# pse84_a0 register map
Vendor: Infineon Technologies; Series: PSE84_A0; File version: 1.0
CPU: CM33 r0p1, little endian, MPU, FPU, VTOR, 3 interrupt priority bits
Registers are 32-bit, read-write, reset 0x0 unless marked. A register's access mark holds for its fields unless they carry their own. Offsets are from the block's base; [hi:lo] are bit positions; lines under a group give offsets from that group; {n}, {i} and the like mark numbered series; 'fields as' and 'values as' point back to an identical list.

## GFXSS (part 2 of 4)
Base 0x44800000
0x1000 GFXSS_DC group — Display Controller.
  0x00 MXDC group — Platform IP standard configuration for DC.
    0x00 CTL — IP control.
      [31] ENABLED — IP enable bit. When disabled (value 0), the functional state of the DCNano core is reset and its clock input gated. Access to MMIO of the core results in an AHB error response. Note, that the effect of this bit is delayed (see STATUS.CORE_RST). The core must be idle (no outstanding or pending AXI transactions) before clearing this bit.
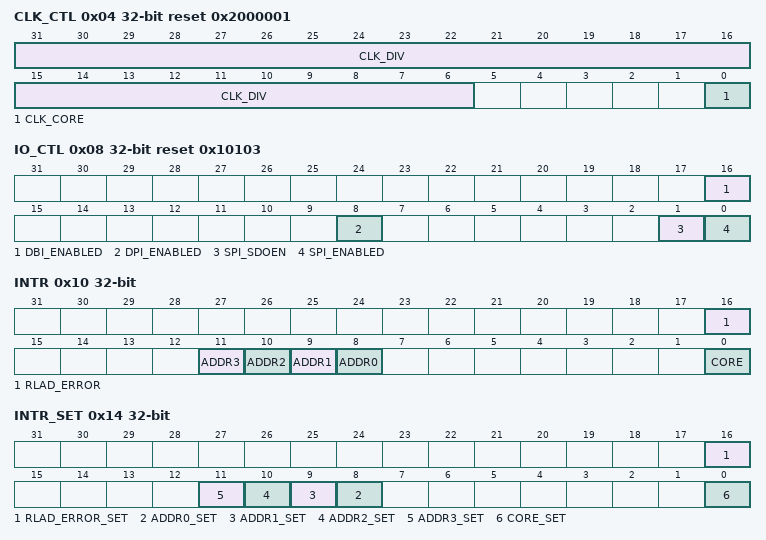
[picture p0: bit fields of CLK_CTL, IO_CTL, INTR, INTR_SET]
    0x04 CLK_CTL reset 0x2000001 — Clock control.
      [31:6] CLK_DIV — Setup of the fractional divider to generate clk_hf_div. In DPI mode the output is the pixel clock. In DBI Type C mode it's two times the serial clock. Format of programmed value is unsigned fix-point 10.16. It must not be set to a value smaller than 2.0 (= 0x020000). It can be set to 0, which results in no clock being generated. Change only while CTL.ENABLED is off.
      [0] CLK_CORE — Setup for DC core and AXI clock. Must only be set to 0 if clk_hf is not faster than 200 MHz. Change only while CTL.ENABLED is off.
        0=HF_DIV1 (Core clock is clk_hf.); 1=HF_DIV2 (Core clock is clk_hf divided by 2.)
    0x08 IO_CTL reset 0x10103 — IO enable control.
      [16] DBI_ENABLED — Enable control for IO cells in DBI Type A/B mode (1 = enabled). CTL.ENABLED must also be 1.
      [8] DPI_ENABLED — Enable control for IO cells in DPI mode (1 = enabled). CTL.ENABLED must also be 1.
      [1] SPI_SDOEN — Controls if the enable for spi_dout is separately controlled by the DCNano core with dbiTypecSdoEn signal (0 = yes, 1 = no). Field has no effect if SPI_ENABLED is 0.
      [0] SPI_ENABLED — Enable control for IO cells in DBI Type C mode (1 = enabled). CTL.ENABLED must also be 1.
    0x0C STATUS ro reset 0x1 — IP status.
      [0] CORE_RST — Reset state of the DCNano core (1 = in reset). This state is delayed to GFXSS_DC reset. After reset de-activation it has to be checked for value 0 before the core can be used. After activation it has to be checked for value 1 before turning off the external clk_hf source.
    0x10 INTR — Interrupt status.
      [16] RLAD_ERROR — The RLAD decoder has entered fail state (see RLAD_STATUS register). Writing a '1' to this field will reset the bit.
      [n+8] ADDR{n} (n=0..3) — Read access to INT_ADDR{n} completed. Writing a '1' to this field will reset the bit.
      [0] CORE — DCNano core has signalled an interrupt. Writing a '1' to this field will reset the bit. Interrupt status inside the core is not affected by this.
    0x14 INTR_SET — Interrupt set bits.
      [16] RLAD_ERROR_SET — Write this field with '1' to set corresponding INTR field (a write of '0' has no effect).
      [n+8] ADDR{n}_SET (n=0..3) — Write this field with '1' to set corresponding INTR field (a write of '0' has no effect).
      [0] CORE_SET — Write this field with '1' to set corresponding INTR field (a write of '0' has no effect).
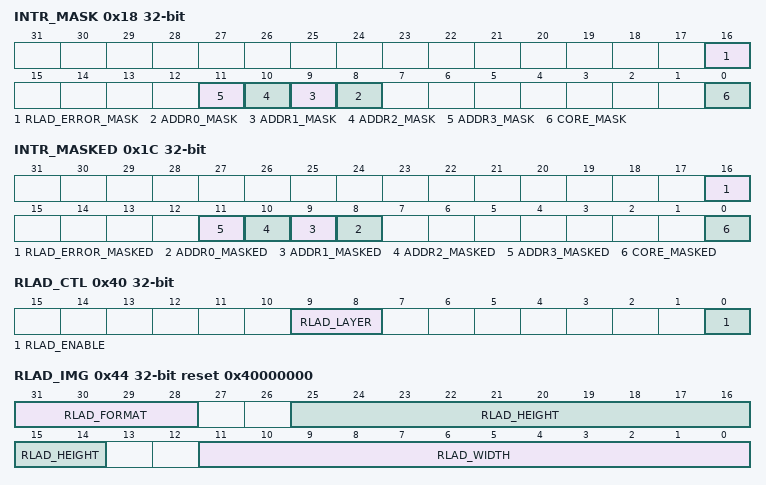
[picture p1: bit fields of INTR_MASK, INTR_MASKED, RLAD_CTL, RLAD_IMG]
    0x18 INTR_MASK — Interrupt mask bits.
      [16] RLAD_ERROR_MASK — Mask for corresponding field in INTR register.
      [n+8] ADDR{n}_MASK (n=0..3) — Mask for corresponding field in INTR register.
      [0] CORE_MASK — Mask for corresponding field in INTR register.
    0x1C INTR_MASKED ro — Interrupt masked bits.
      [16] RLAD_ERROR_MASKED — Logical AND of corresponding INTR and INTR_MASK fields.
      [n+8] ADDR{n}_MASKED (n=0..3) — Logical AND of corresponding INTR and INTR_MASK fields.
      [0] CORE_MASKED — Logical AND of corresponding INTR and INTR_MASK fields.
    0x20 ADDR0_INT — Address 0 for interrupt generation.
      [31:0] ADDR0_INT — A completed read access to this memory address will set INTR.ADDR0. The shadow values of all address fields are copied into the active configuration when a display frame has completed and GCREGPANELCONTROL_VALID was set before in DCNANO.
    {0x20+4k} ADDR{k}_INT (k=1..3) — Address {k} for interrupt generation.
      [31:0] ADDR{k}_INT — A completed read access to this memory address will set INTR.ADDR{k}.
    0x40 RLAD_CTL — Control options for the RLAD decoder.
      [9:8] RLAD_LAYER
      [0] RLAD_ENABLE — When set to 0, the RLAD decoder is disabled. It's clock tree is gated and the functional logic reset. All RLAD configuration fields, including this enable field, are shadowed. The shadow values are copied into the active configuration when a display frame has completed and GCREGPANELCONTROL_VALID was set before in DCNANO. Once the load of shadows has been initiated by setting the VALID flag, the RLAD configuration fields must not be changed again before the frame complete interrupt. Beside inconsistent setup for a display frame, this can lead to data corruption of the active configuration.
    0x44 RLAD_IMG reset 0x40000000 — Properties of the uncompressed image.
      [31:28] RLAD_FORMAT — Color format of the uncompressed image. The RLAD block converts the configured format after decompression to ARGB8888, which is the format the DC layer has to be configured for (in linear order and with component swizzle ARGB). Alpha value is set to 255 for RGB and GRAY formats.
        1=ARGB4444 (N/A); 2=ARGB1555 (N/A); 3=RGB565 (N/A); 4=ARGB8888 (N/A); 5=RGB888 (N/A); 6=RGB666 (N/A); 7=RGB444 (N/A); 8=GRAY8 (N/A); 9=GRAY6 (N/A); 10=GRAY4 (N/A)
      [25:14] RLAD_HEIGHT — Height of the image in number of lines minus one. The DC layer must be setup for the same height.
      [11:0] RLAD_WIDTH — Width of the image in number of pixels minus one. The DC layer must be setup for the same width.
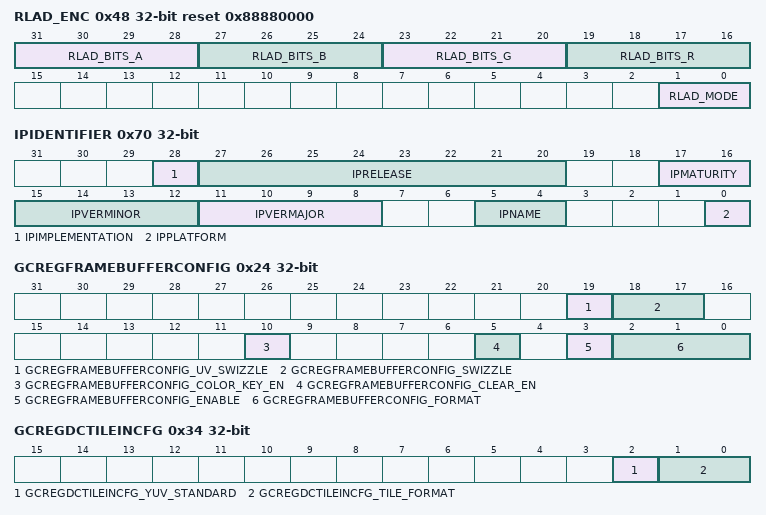
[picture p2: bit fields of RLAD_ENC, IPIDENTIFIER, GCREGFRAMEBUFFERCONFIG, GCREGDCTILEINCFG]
    0x48 RLAD_ENC reset 0x88880000 — Configuration of the encoder that compressed the image.
      [31:28] RLAD_BITS_A — Max number of alpha channel bits (used for RLAD modes only).
      [27:24] RLAD_BITS_B — Max number of blue channel bits (used for RLAD modes only).
      [23:20] RLAD_BITS_G — Max number of green channel bits (used for RLAD modes only).
      [19:16] RLAD_BITS_R — Max number of red channel bits (used for RLAD modes only).
      [1:0] RLAD_MODE — Encoding mode.
        0=RLAD (Run-Length Adaptive Dithering (lossy).); 1=RLAD_UNIFORM (RLAD with uniform package size (less efficient, but can force a consistent read bandwidth if needed).); 2=RLA (Run-Length Adaptive (lossless).); 3=RL (Standard Run-Length (lossless).)
    0x4C RLAD_BUF0 — Properties of the compressed image data buffer.
      [31:7] RLAD_ADDRESS — Base address of the encoded image buffer in multiple of 128 bytes. The DC layer must be configured to the same base address and with the smallest possible stride value (aligned to 128 bytes).
    0x50 RLAD_BUF1 — Properties of the compressed image data buffer.
      [28:0] RLAD_SIZE — Size of the the encoded image in number of 32-bit words minus one. The buffer must be readable to the subsequent 128 bytes boundary.
    0x54 RLAD_STATUS ro — RLAD decoder status.
      [2:0] RLAD_FAILED — The fail state is activated in case an error condition has been detected. This will also trigger the RLAD_ERROR interrupt. In that state the RLAD decoding process is stopped and the DC will only read null data. No more read accesses to the memory buffer are generated. The fail state is quit by disabling the DC via CTL.ENABLED.
        0=OFF (No fail state (= normal operation).); 1=AXI_ERROR (An AXI error response was received when reading compressed image data.); 2=BUF_TOO_SMALL (The RLAD_SIZE setting is inconsistent with the compressed image data (image decompression not complete when end of buffer was reached).); 3=BUF_TOO_LARGE (The RLAD_SIZE setting is inconsistent with the compressed image data (image decompression completed before end of buffer was reached).); 4=DC_INVALID_SIZE (The DC was reading the first pixel of a frame when it was not expected. This means an inconsistent setup of RLAD and DC configuration.); 5=DC_INVALID_FORMAT (The DC was reading data with an unexpected burst length. This means an invalid buffer format was configured.)
    0x70 IPIDENTIFIER ro reset not defined — GFXSS IP and desig release identification (with DC, GPU and MIPIDSI).
      [28] IPIMPLEMENTATION — Implementation type.
        0=RTL (Logic design for FPGA and ASIC synthesis.)
      [27:20] IPRELEASE — Release ID. This is independently set for each implementation type. The value starts with 0 and is increased for every new release of a an IP project, which is defined by IPName, IPVERMAJOR and IPVERMINOR.
      [17:16] IPMATURITY — IP Maturity Status with Chip Integration Cycle targets (CIC). This is independently set for each implementation type.
        0=NONE (Undefined.); 1=CPR (Implementation incomplete (for CIC Physical Readiness Review).); 2=CMR (Implementation complete (for CIC Mock Review).); 3=CFR (Verification complete (for CIC Final Handoff Review).)
      [15:12] IPVERMINOR — Minor IP Version Number.
      [11:8] IPVERMAJOR — Major IP Version Number.
      [5:4] IPNAME — Name of IP family.
        0=GFXSS (Graphics Subsystem with Display Controller for Low Power applications.)
      [0] IPPLATFORM — Name of SOC Platform.
        0=MXS22_S22 (MXS22 Base Variant.)
  0x800 DCNANO group — Host Interface Registers
    0x00 GCREGDCCHIPREV ro reset not defined — Chip Revision Register. Shows the revision for the chip in BCD. This register has no set reset value. It varies with the implementation. READ ONLY.
      [31:0] GCREGDCCHIPREV_REV — Revision. The reset value for this field is subject to change and may be ignored during test.
    0x04 GCREGDCCHIPDATE ro reset not defined — Chip Date Register. Shows the release date for the IP in YYYYMMDD (year, month. day) format. This register has no set reset value. It varies with the implementation. READ ONLY.
      [31:0] GCREGDCCHIPDATE_DATE — Date. The reset value for this field changes per release and may be ignored during test. You can read the accurate value from the RTL file because the actual value may be later than the document release time.
    0x08 GCREGDCCHIPPATCHREV ro reset not defined — Patch Revision Register. Patch revision level for the chip. READ ONLY.
      [31:0] GCREGDCCHIPPATCHREV_PATCH_REV — Patch revision. The reset value for this field changes per release and may be ignored during test. You can read the accurate value from the RTL file because the actual value may be later than the document release time.
    0x0C GCREGDCPRODUCTID ro reset 0x2080001 — Product Identification Register. READ ONLY.
      [31:0] GCREGDCPRODUCTID_PRODUCT_ID — Product ID. Bits 3:0 contain Product GRADE_LEVEL. 1 indicates level is Nano. Bits 23:4 contain Product NUM, product number. None for DCNano; 8000 for DC8000 Series. Bits 27:24 contain Product TYPE. 2 indicates Display Controller.
    0x24 GCREGFRAMEBUFFERCONFIG — Frame Buffer Configuration Register. Frame Buffer and Timing control. NOTE.. This register is double buffered.
      [19] GCREGFRAMEBUFFERCONFIG_UV_SWIZZLE — NOTE: This field is double buffered.
      [18:17] GCREGFRAMEBUFFERCONFIG_SWIZZLE — NOTE: This field is double buffered.
        0=ARGB ((none)); 1=RGBA ((none)); 2=ABGR ((none)); 3=BGRA ((none))
      [10] GCREGFRAMEBUFFERCONFIG_COLOR_KEY_EN — Enable or disable color key. NOTE: This field is double buffered.
        0=DISABLED ((none)); 1=ENABLED ((none))
      [5] GCREGFRAMEBUFFERCONFIG_CLEAR_EN — Enable or disable clear. NOTE: This field is double buffered.
        0=DISABLED ((none)); 1=ENABLED ((none))
      [3] GCREGFRAMEBUFFERCONFIG_ENABLE — Enable this layer or disable this layer. NOTE: This field is double buffered.
        0=DISABLED ((none)); 1=ENABLED ((none))
      [2:0] GCREGFRAMEBUFFERCONFIG_FORMAT — The format of the frame buffer. None means there is no frame buffer and the display controller will not produce any output. NOTE: This field is double buffered.
        0=NONE; 1=A4R4G4B4 ((none)); 2=A1R5G5B5 ((none)); 3=R5G6B5 ((none)); 4=A8R8G8B8 ((none))
    0x28 GCREGFRAMEBUFFERADDRESS — Frame Buffer Base Address Register. Starting address of the frame buffer. NOTE.. This register is double buffered.
      [31:0] GCREGFRAMEBUFFERADDRESS_ADDRESS — 32 bit address.
    0x2C GCREGFRAMEBUFFERSTRIDE — Frame Buffer Stride Register. Stride of the frame buffer in bytes. NOTE.. This register is double buffered.
      [16:0] GCREGFRAMEBUFFERSTRIDE_STRIDE — Number of bytes from start of one line to next line. NOTE: This field is double buffered.
    0x34 GCREGDCTILEINCFG — Tile Input Configuration Register. Tile input configuration. NOTE.. This register is double buffered.
      [2] GCREGDCTILEINCFG_YUV_STANDARD — YUV standard select. NOTE: This field is double buffered.
        0=BT601 ((none)); 1=BT709 ((none))
      [1:0] GCREGDCTILEINCFG_TILE_FORMAT — Tile input data format 0 means non-tile input. NOTE: This field is double buffered.
        0=NONE; 1=ARGB8888 ((none)); 2=YUY2 ((none)); 3=NV12 ((none))
    0x38 GCREGDCTILEUVFRAMEBUFFERADR — Frame Buffer Tiled UV Base Address Register. UV frame buffer address when tile input. NOTE.. This register is double buffered.
      [31:0] GCREGDCTILEUVFRAMEBUFFERADR_ADDRESS — UV frame buffer address when tile input NOTE: This field is double buffered.
    0x3C GCREGDCTILEUVFRAMEBUFFERSTR — Frame Buffer Tiled UV Stride Register. UV frame buffer stride when tile input NOTE.. This register is double buffered.
      [15:0] GCREGDCTILEUVFRAMEBUFFERSTR_STRIDE — UV frame buffer stride when tile input NOTE: This field is double buffered.
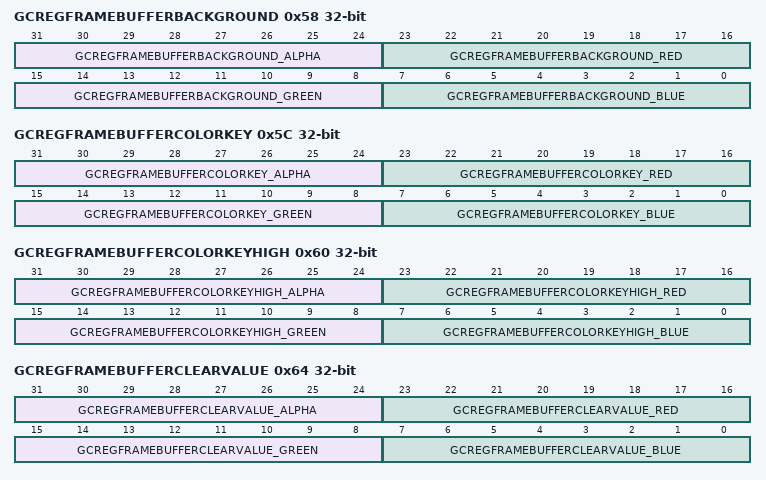
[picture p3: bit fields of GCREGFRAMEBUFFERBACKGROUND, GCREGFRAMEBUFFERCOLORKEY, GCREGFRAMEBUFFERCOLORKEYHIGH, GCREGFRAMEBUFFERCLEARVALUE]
    0x58 GCREGFRAMEBUFFERBACKGROUND — Framebuffer background color. NOTE.. This register is double buffered.
      [31:24] GCREGFRAMEBUFFERBACKGROUND_ALPHA — NOTE: This field is double buffered.
      [23:16] GCREGFRAMEBUFFERBACKGROUND_RED — NOTE: This field is double buffered.
      [15:8] GCREGFRAMEBUFFERBACKGROUND_GREEN — NOTE: This field is double buffered.
      [7:0] GCREGFRAMEBUFFERBACKGROUND_BLUE — NOTE: This field is double buffered.
    0x5C GCREGFRAMEBUFFERCOLORKEY — Framebuffer Color Key Start Address Register. Start of color key range of framebuffer. NOTE.. This register is double buffered.
      [31:24] GCREGFRAMEBUFFERCOLORKEY_ALPHA — 8 bit alpha value.
      [23:16] GCREGFRAMEBUFFERCOLORKEY_RED — 8 bit red color.
      [15:8] GCREGFRAMEBUFFERCOLORKEY_GREEN — 8 bit green color.
      [7:0] GCREGFRAMEBUFFERCOLORKEY_BLUE — 8 bit blue color.
    0x60 GCREGFRAMEBUFFERCOLORKEYHIGH — Framebuffer Color Key End Address Register. End of color key range of framebuffer. NOTE.. This register is double buffered.
      [31:24] GCREGFRAMEBUFFERCOLORKEYHIGH_ALPHA — 8 bit alpha value.
      [23:16] GCREGFRAMEBUFFERCOLORKEYHIGH_RED — 8 bit red color.
      [15:8] GCREGFRAMEBUFFERCOLORKEYHIGH_GREEN — 8 bit green color.
      [7:0] GCREGFRAMEBUFFERCOLORKEYHIGH_BLUE — 8 bit blue color.
    0x64 GCREGFRAMEBUFFERCLEARVALUE — Framebuffer Clear Value Register. Clear value used when dcregFrameBufferConfig.Clear is enabled, format is A8R8G8B8. NOTE.. This register is double buffered.
      [31:24] GCREGFRAMEBUFFERCLEARVALUE_ALPHA — 8 bit alpha value.
      [23:16] GCREGFRAMEBUFFERCLEARVALUE_RED — 8 bit red color.
      [15:8] GCREGFRAMEBUFFERCLEARVALUE_GREEN — 8 bit green color.
      [7:0] GCREGFRAMEBUFFERCLEARVALUE_BLUE — 8 bit blue color.
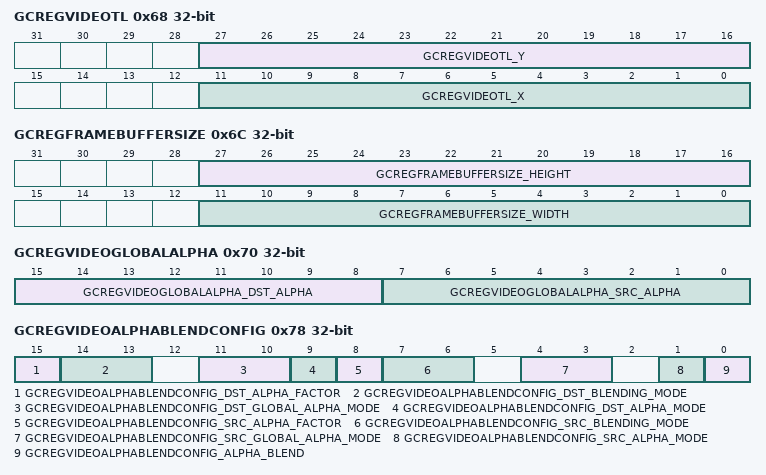
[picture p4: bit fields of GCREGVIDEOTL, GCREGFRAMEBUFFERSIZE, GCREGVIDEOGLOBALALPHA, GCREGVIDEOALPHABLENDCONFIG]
    0x68 GCREGVIDEOTL — Top left coordinate of panel pixel where the video should start. Be aware there is no panning inside the video. NOTE.. This register is double buffered.
      [27:16] GCREGVIDEOTL_Y — Top boundary of video window. NOTE: This field is double buffered.
      [11:0] GCREGVIDEOTL_X — Left boundary of video window. NOTE: This field is double buffered.
    0x6C GCREGFRAMEBUFFERSIZE — video size information. NOTE.. This register is double buffered.
      [27:16] GCREGFRAMEBUFFERSIZE_HEIGHT — video height. NOTE: This field is double buffered.
      [11:0] GCREGFRAMEBUFFERSIZE_WIDTH — video width. NOTE: This field is double buffered.
    0x70 GCREGVIDEOGLOBALALPHA — Global alpha for the video. NOTE.. This register is double buffered.
      [15:8] GCREGVIDEOGLOBALALPHA_DST_ALPHA — Destination alpha for video. NOTE: This field is double buffered.
      [7:0] GCREGVIDEOGLOBALALPHA_SRC_ALPHA — Source alpha for video. NOTE: This field is double buffered.
    0x74 GCREGBLENDSTACKORDER — Set the video, overlay0, overlay1 order for blend. The 1st is the lowest layer, the 2nd is the middle layer, the 3rd is the highest layer. NOTE.. This register is double buffered.
      [2:0] GCREGBLENDSTACKORDER_ORDER — NOTE: This field is double buffered.
        0=VIDEO_OVERLAY0_OVERLAY1 ((none)); 1=VIDEO_OVERLAY1_OVERLAY0 ((none)); 2=OVERLAY0_VIDEO_OVERLAY1 ((none)); 3=OVERLAY0_OVERLAY1_VIDEO ((none)); 4=OVERLAY1_VIDEO_OVERLAY0 ((none)); 5=OVERLAY1_OVERLAY0_VIDEO ((none))
    0x78 GCREGVIDEOALPHABLENDCONFIG — Alpha Blending Configuration Register. NOTE.. This register is double buffered.
      [15] GCREGVIDEOALPHABLENDCONFIG_DST_ALPHA_FACTOR — Destination blending factor is calculated from Dst alpha.
        0=DISABLED ((none)); 1=ENABLED ((none))
      [14:13] GCREGVIDEOALPHABLENDCONFIG_DST_BLENDING_MODE — (none)
        0=ZERO ((none)); 1=ONE ((none)); 2=NORMAL ((none)); 3=INVERSED ((none))
      [11:10] GCREGVIDEOALPHABLENDCONFIG_DST_GLOBAL_ALPHA_MODE — (none)
        0=NORMAL ((none)); 1=GLOBAL ((none)); 2=SCALED ((none))
      [9] GCREGVIDEOALPHABLENDCONFIG_DST_ALPHA_MODE — (none)
        0=NORMAL ((none)); 1=INVERSED ((none))
      [8] GCREGVIDEOALPHABLENDCONFIG_SRC_ALPHA_FACTOR — Src Blending factor is calculated from Src alpha.
        0=DISABLED ((none)); 1=ENABLED ((none))
      [7:6] GCREGVIDEOALPHABLENDCONFIG_SRC_BLENDING_MODE — (none)
        values as GCREGVIDEOALPHABLENDCONFIG_DST_BLENDING_MODE
      [4:3] GCREGVIDEOALPHABLENDCONFIG_SRC_GLOBAL_ALPHA_MODE — (none)
        0=NORMAL ((none)); 1=GLOBAL ((none)); 2=SCALED ((none))
      [1] GCREGVIDEOALPHABLENDCONFIG_SRC_ALPHA_MODE — (none)
        0=NORMAL ((none)); 1=INVERSED ((none))
      [0] GCREGVIDEOALPHABLENDCONFIG_ALPHA_BLEND — (none)
        0=DISABLED ((none)); 1=ENABLED ((none))
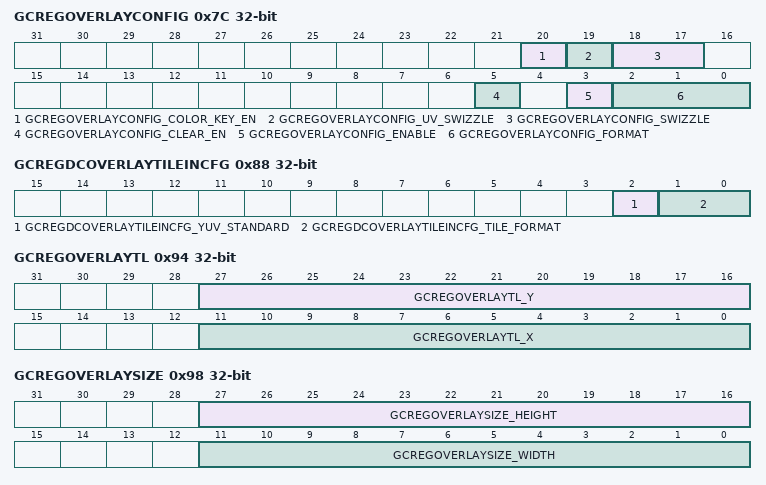
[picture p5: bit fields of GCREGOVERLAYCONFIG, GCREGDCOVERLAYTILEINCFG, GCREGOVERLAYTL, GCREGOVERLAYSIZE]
    0x7C GCREGOVERLAYCONFIG — Overlay Configuration Register. Overlay control. NOTE.. This register is double buffered.
      [20] GCREGOVERLAYCONFIG_COLOR_KEY_EN — Enable or disable color key. NOTE: This field is double buffered.
        0=DISABLED ((none)); 1=ENABLED ((none))
      [19] GCREGOVERLAYCONFIG_UV_SWIZZLE — NOTE: This field is double buffered.
      [18:17] GCREGOVERLAYCONFIG_SWIZZLE — NOTE: This field is double buffered.
        values as GFXSS_DC.DCNANO.GCREGFRAMEBUFFERCONFIG.GCREGFRAMEBUFFERCONFIG_SWIZZLE
      [5] GCREGOVERLAYCONFIG_CLEAR_EN — Enable or disable clear. NOTE: This field is double buffered.
        0=DISABLED ((none)); 1=ENABLED ((none))
      [3] GCREGOVERLAYCONFIG_ENABLE — Enable this overlay layer. NOTE: This field is double buffered.
        0=DISABLE ((none)); 1=ENABLE ((none))
      [2:0] GCREGOVERLAYCONFIG_FORMAT — The format of the overlay. None means there is no overlay. NOTE: This field is double buffered.
        values as GFXSS_DC.DCNANO.GCREGFRAMEBUFFERCONFIG.GCREGFRAMEBUFFERCONFIG_FORMAT
    0x80 GCREGOVERLAYADDRESS — Starting address of the overlay. NOTE.. This register is double buffered.
      [31:0] GCREGOVERLAYADDRESS_ADDRESS — 32 bit address.
    0x84 GCREGOVERLAYSTRIDE — Stride of the overlay in bytes. NOTE.. This register is double buffered.
      [16:0] GCREGOVERLAYSTRIDE_STRIDE — Number of bytes from start of one line to next line.
    0x88 GCREGDCOVERLAYTILEINCFG — Tile Input Configuration Register. Tile input configuration. NOTE.. This register is double buffered.
      [2] GCREGDCOVERLAYTILEINCFG_YUV_STANDARD — YUV standard select. NOTE: This field is double buffered.
        0=BT601 ((none)); 1=BT709 ((none))
      [1:0] GCREGDCOVERLAYTILEINCFG_TILE_FORMAT — Tile input data format 0 means non-tile input NOTE: This field is double buffered.
        values as GFXSS_DC.DCNANO.GCREGDCTILEINCFG.GCREGDCTILEINCFG_TILE_FORMAT
    0x8C GCREGDCTILEUVOVERLAYADR — Starting address of the overlay UV. NOTE.. This register is double buffered.
      [31:0] GCREGDCTILEUVOVERLAYADR_ADDRESS — 32 bit address.
    0x90 GCREGDCTILEUVOVERLAYSTR — Stride of the overlay UV in bytes. NOTE.. This register is double buffered.
      [15:0] GCREGDCTILEUVOVERLAYSTR_STRIDE — Number of bytes from start of one line to next line. NOTE: This field is double buffered.
    0x94 GCREGOVERLAYTL — Top left coordinate of panel pixel where the overlay should start. Be aware there is no panning inside the overlay. NOTE.. This register is double buffered.
      [27:16] GCREGOVERLAYTL_Y — Top boundary of overlay window.
      [11:0] GCREGOVERLAYTL_X — Left boundary of overlay window.
    0x98 GCREGOVERLAYSIZE — overlay size information. NOTE.. This register is double buffered.
      [27:16] GCREGOVERLAYSIZE_HEIGHT — overlay height.
      [11:0] GCREGOVERLAYSIZE_WIDTH — overlay width.
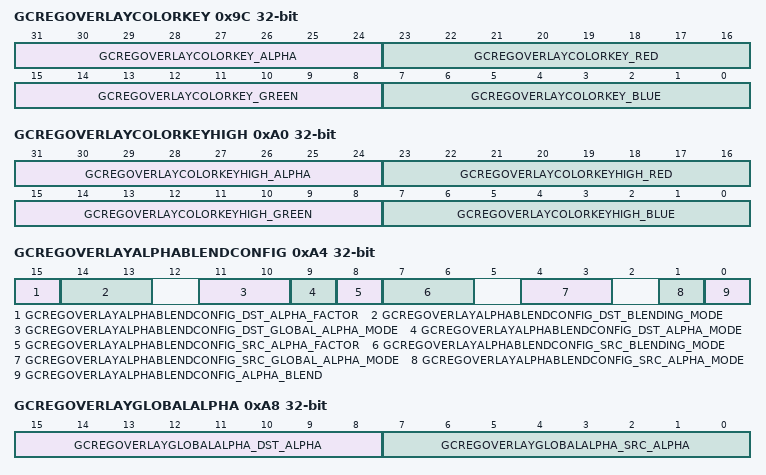
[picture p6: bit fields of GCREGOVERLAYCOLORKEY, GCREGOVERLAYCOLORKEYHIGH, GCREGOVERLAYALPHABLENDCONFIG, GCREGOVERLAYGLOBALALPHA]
    0x9C GCREGOVERLAYCOLORKEY — Overlay Color Key Start Address Register. Start of color key range for overlay. NOTE.. This register is double buffered.
      [31:24] GCREGOVERLAYCOLORKEY_ALPHA — 8 bit alpha value.
      [23:16] GCREGOVERLAYCOLORKEY_RED — 8 bit red color.
      [15:8] GCREGOVERLAYCOLORKEY_GREEN — 8 bit green color.
      [7:0] GCREGOVERLAYCOLORKEY_BLUE — 8 bit blue color.
    0xA0 GCREGOVERLAYCOLORKEYHIGH — Overlay Color Key End Address Register. End of color key range for overlay. NOTE.. This register is double buffered.
      [31:24] GCREGOVERLAYCOLORKEYHIGH_ALPHA — 8 bit alpha value.
      [23:16] GCREGOVERLAYCOLORKEYHIGH_RED — 8 bit red color.
      [15:8] GCREGOVERLAYCOLORKEYHIGH_GREEN — 8 bit green color.
      [7:0] GCREGOVERLAYCOLORKEYHIGH_BLUE — 8 bit blue color.
    0xA4 GCREGOVERLAYALPHABLENDCONFIG — Alpha Blending Configuration Register. NOTE.. This register is double buffered.
      [15] GCREGOVERLAYALPHABLENDCONFIG_DST_ALPHA_FACTOR — Destination blending factor is calculated from Dst alpha.
        0=DISABLED ((none)); 1=ENABLED ((none))
      [14:13] GCREGOVERLAYALPHABLENDCONFIG_DST_BLENDING_MODE — (none)
        values as GFXSS_DC.DCNANO.GCREGVIDEOALPHABLENDCONFIG.GCREGVIDEOALPHABLENDCONFIG_DST_BLENDING_MODE
      [11:10] GCREGOVERLAYALPHABLENDCONFIG_DST_GLOBAL_ALPHA_MODE — (none)
        0=NORMAL ((none)); 1=GLOBAL ((none)); 2=SCALED ((none))
      [9] GCREGOVERLAYALPHABLENDCONFIG_DST_ALPHA_MODE — (none)
        0=NORMAL ((none)); 1=INVERSED ((none))
      [8] GCREGOVERLAYALPHABLENDCONFIG_SRC_ALPHA_FACTOR — Src Blending factor is calculated from Src alpha.
        0=DISABLED ((none)); 1=ENABLED ((none))
      [7:6] GCREGOVERLAYALPHABLENDCONFIG_SRC_BLENDING_MODE — (none)
        values as GFXSS_DC.DCNANO.GCREGVIDEOALPHABLENDCONFIG.GCREGVIDEOALPHABLENDCONFIG_DST_BLENDING_MODE
      [4:3] GCREGOVERLAYALPHABLENDCONFIG_SRC_GLOBAL_ALPHA_MODE — (none)
        0=NORMAL ((none)); 1=GLOBAL ((none)); 2=SCALED ((none))
      [1] GCREGOVERLAYALPHABLENDCONFIG_SRC_ALPHA_MODE — (none)
        0=NORMAL ((none)); 1=INVERSED ((none))
      [0] GCREGOVERLAYALPHABLENDCONFIG_ALPHA_BLEND — (none)
        0=DISABLED ((none)); 1=ENABLED ((none))
    0xA8 GCREGOVERLAYGLOBALALPHA — Overlay global alpha value. NOTE.. This register is double buffered.
      [15:8] GCREGOVERLAYGLOBALALPHA_DST_ALPHA — (none)
      [7:0] GCREGOVERLAYGLOBALALPHA_SRC_ALPHA — (none)
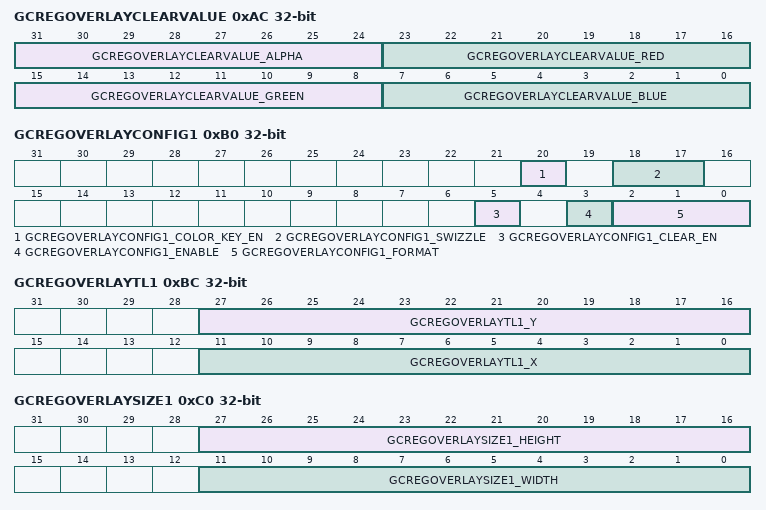
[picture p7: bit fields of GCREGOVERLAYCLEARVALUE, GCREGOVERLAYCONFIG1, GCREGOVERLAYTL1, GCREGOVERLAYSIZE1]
    0xAC GCREGOVERLAYCLEARVALUE — Overlay Clear Value Register. Clear value used when dcregOverlayConfig.Clear is enabled, Format is A8R8G8B8. NOTE.. This register is double buffered.
      [31:24] GCREGOVERLAYCLEARVALUE_ALPHA — 8 bit alpha value.
      [23:16] GCREGOVERLAYCLEARVALUE_RED — 8 bit red color.
      [15:8] GCREGOVERLAYCLEARVALUE_GREEN — 8 bit green color.
      [7:0] GCREGOVERLAYCLEARVALUE_BLUE — 8 bit blue color.
    0xB0 GCREGOVERLAYCONFIG1 — Overlay Configuration Register. Overlay control. NOTE.. This register is double buffered.
      [20] GCREGOVERLAYCONFIG1_COLOR_KEY_EN — Enable or disable color key. NOTE: This field is double buffered.
        0=DISABLED ((none)); 1=ENABLED ((none))
      [18:17] GCREGOVERLAYCONFIG1_SWIZZLE — NOTE: This field is double buffered.
        values as GFXSS_DC.DCNANO.GCREGFRAMEBUFFERCONFIG.GCREGFRAMEBUFFERCONFIG_SWIZZLE
      [5] GCREGOVERLAYCONFIG1_CLEAR_EN — Enable or disable clear. NOTE: This field is double buffered.
        0=DISABLED ((none)); 1=ENABLED ((none))
      [3] GCREGOVERLAYCONFIG1_ENABLE — Enable this overlay layer. NOTE: This field is double buffered.
        0=DISABLE ((none)); 1=ENABLE ((none))
      [2:0] GCREGOVERLAYCONFIG1_FORMAT — The format of the overlay. None means there is no overlay. NOTE: This field is double buffered.
        values as GFXSS_DC.DCNANO.GCREGFRAMEBUFFERCONFIG.GCREGFRAMEBUFFERCONFIG_FORMAT
    0xB4 GCREGOVERLAYADDRESS1 — Starting address of the overlay. NOTE.. This register is double buffered.
      [31:0] GCREGOVERLAYADDRESS1_ADDRESS — 32 bit address.
    0xB8 GCREGOVERLAYSTRIDE1 — Stride of the overlay in bytes. NOTE.. This register is double buffered.
      [16:0] GCREGOVERLAYSTRIDE1_STRIDE — Number of bytes from start of one line to next line.
    0xBC GCREGOVERLAYTL1 — Top left coordinate of panel pixel where the overlay should start. Be aware there is no panning inside the overlay. NOTE.. This register is double buffered.
      [27:16] GCREGOVERLAYTL1_Y — Top boundary of overlay window.
      [11:0] GCREGOVERLAYTL1_X — Left boundary of overlay window.
    0xC0 GCREGOVERLAYSIZE1 — overlay1 size information. NOTE.. This register is double buffered.
      [27:16] GCREGOVERLAYSIZE1_HEIGHT — overlay1 height.
      [11:0] GCREGOVERLAYSIZE1_WIDTH — overlay1 width.
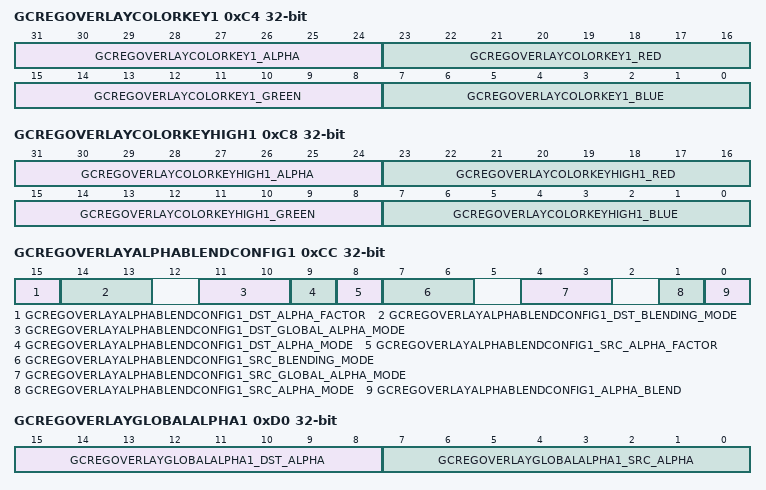
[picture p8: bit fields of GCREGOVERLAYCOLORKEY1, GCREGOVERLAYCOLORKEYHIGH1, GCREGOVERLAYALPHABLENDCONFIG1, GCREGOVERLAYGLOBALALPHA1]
    0xC4 GCREGOVERLAYCOLORKEY1 — Overlay Color Key Start Address Register. Start of color key range for overlay. NOTE.. This register is double buffered.
      [31:24] GCREGOVERLAYCOLORKEY1_ALPHA — 8 bit alpha value.
      [23:16] GCREGOVERLAYCOLORKEY1_RED — 8 bit red color.
      [15:8] GCREGOVERLAYCOLORKEY1_GREEN — 8 bit green color.
      [7:0] GCREGOVERLAYCOLORKEY1_BLUE — 8 bit blue color.
    0xC8 GCREGOVERLAYCOLORKEYHIGH1 — Overlay Color Key End Address Register. End of color key range for overlay. NOTE.. This register is double buffered.
      [31:24] GCREGOVERLAYCOLORKEYHIGH1_ALPHA — 8 bit alpha value.
      [23:16] GCREGOVERLAYCOLORKEYHIGH1_RED — 8 bit red color.
      [15:8] GCREGOVERLAYCOLORKEYHIGH1_GREEN — 8 bit green color.
      [7:0] GCREGOVERLAYCOLORKEYHIGH1_BLUE — 8 bit blue color.
    0xCC GCREGOVERLAYALPHABLENDCONFIG1 — Alpha Blending Configuration Register. NOTE.. This register is double buffered.
      [15] GCREGOVERLAYALPHABLENDCONFIG1_DST_ALPHA_FACTOR — Destination blending factor is calculated from Dst alpha.
        0=DISABLED ((none)); 1=ENABLED ((none))
      [14:13] GCREGOVERLAYALPHABLENDCONFIG1_DST_BLENDING_MODE — (none)
        values as GFXSS_DC.DCNANO.GCREGVIDEOALPHABLENDCONFIG.GCREGVIDEOALPHABLENDCONFIG_DST_BLENDING_MODE
      [11:10] GCREGOVERLAYALPHABLENDCONFIG1_DST_GLOBAL_ALPHA_MODE — (none)
        0=NORMAL ((none)); 1=GLOBAL ((none)); 2=SCALED ((none))
      [9] GCREGOVERLAYALPHABLENDCONFIG1_DST_ALPHA_MODE — (none)
        0=NORMAL ((none)); 1=INVERSED ((none))
      [8] GCREGOVERLAYALPHABLENDCONFIG1_SRC_ALPHA_FACTOR — Src Blending factor is calculated from Src alpha.
        0=DISABLED ((none)); 1=ENABLED ((none))
      [7:6] GCREGOVERLAYALPHABLENDCONFIG1_SRC_BLENDING_MODE — (none)
        values as GFXSS_DC.DCNANO.GCREGVIDEOALPHABLENDCONFIG.GCREGVIDEOALPHABLENDCONFIG_DST_BLENDING_MODE
      [4:3] GCREGOVERLAYALPHABLENDCONFIG1_SRC_GLOBAL_ALPHA_MODE — (none)
        0=NORMAL ((none)); 1=GLOBAL ((none)); 2=SCALED ((none))
      [1] GCREGOVERLAYALPHABLENDCONFIG1_SRC_ALPHA_MODE — (none)
        0=NORMAL ((none)); 1=INVERSED ((none))
      [0] GCREGOVERLAYALPHABLENDCONFIG1_ALPHA_BLEND — (none)
        0=DISABLED ((none)); 1=ENABLED ((none))
    0xD0 GCREGOVERLAYGLOBALALPHA1 — Overlay global alpha value. NOTE.. This register is double buffered.
      [15:8] GCREGOVERLAYGLOBALALPHA1_DST_ALPHA — (none)
      [7:0] GCREGOVERLAYGLOBALALPHA1_SRC_ALPHA — (none)
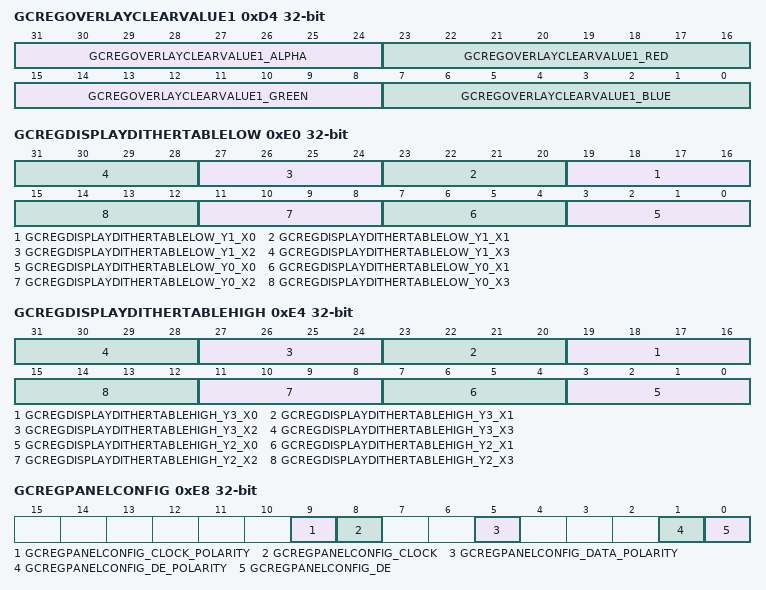
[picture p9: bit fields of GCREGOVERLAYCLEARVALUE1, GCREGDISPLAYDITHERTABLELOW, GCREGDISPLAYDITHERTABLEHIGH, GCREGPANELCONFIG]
    0xD4 GCREGOVERLAYCLEARVALUE1 — Overlay Clear Value Register. Clear value used when dcregOverlayConfig.Clear is enabled, Format is A8R8G8B8. NOTE.. This register is double buffered.
      [31:24] GCREGOVERLAYCLEARVALUE1_ALPHA — 8 bit alpha value.
      [23:16] GCREGOVERLAYCLEARVALUE1_RED — 8 bit red color.
      [15:8] GCREGOVERLAYCLEARVALUE1_GREEN — 8 bit green color.
      [7:0] GCREGOVERLAYCLEARVALUE1_BLUE — 8 bit blue color.
    0xE0 GCREGDISPLAYDITHERTABLELOW — Dither Threshold Table Register.
      [4n+19:4n+16] GCREGDISPLAYDITHERTABLELOW_Y1_X{n} (n=0..3) — Dither threshold value for x,y={n},1.
      [4n+3:4n] GCREGDISPLAYDITHERTABLELOW_Y0_X{n} (n=0..3) — Dither threshold value for x,y={n},0.
    0xE4 GCREGDISPLAYDITHERTABLEHIGH — Dither Threshold Table Register.
      [4n+19:4n+16] GCREGDISPLAYDITHERTABLEHIGH_Y3_X{n} (n=0..3) — Dither threshold value for x,y={n},3.
      [4n+3:4n] GCREGDISPLAYDITHERTABLEHIGH_Y2_X{n} (n=0..3) — Dither threshold value for x,y={n},2.
    0xE8 GCREGPANELCONFIG — Panel Configuration Register.
      [9] GCREGPANELCONFIG_CLOCK_POLARITY — Clock polarity.
        0=POSITIVE ((none)); 1=NEGATIVE ((none))
      [8] GCREGPANELCONFIG_CLOCK — Clock enable/disable.
        0=DISABLED ((none)); 1=ENABLED ((none))
      [5] GCREGPANELCONFIG_DATA_POLARITY — Data polarity.
        0=POSITIVE ((none)); 1=NEGATIVE ((none))
      [1] GCREGPANELCONFIG_DE_POLARITY — Data Enable polarity.
        0=POSITIVE ((none)); 1=NEGATIVE ((none))
      [0] GCREGPANELCONFIG_DE — Data Enable enabled/disabled.
        0=DISABLED ((none)); 1=ENABLED ((none))
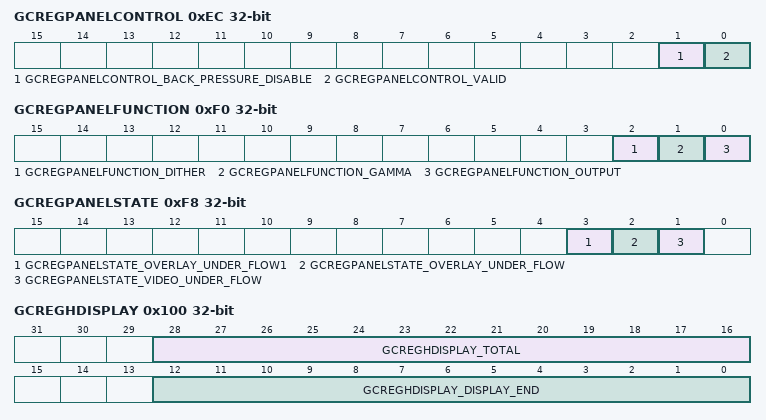
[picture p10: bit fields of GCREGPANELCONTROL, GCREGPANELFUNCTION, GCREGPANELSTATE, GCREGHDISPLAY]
    0xEC GCREGPANELCONTROL — Panel control Register.
      [1] GCREGPANELCONTROL_BACK_PRESSURE_DISABLE — Interface of DPI
        0=NO ((none)); 1=YES ((none))
      [0] GCREGPANELCONTROL_VALID — The valid field defines whether we can copy a new set of registers at the next VBLANK or not. This ensures a frame will always start with a valid working set if this register is programmed last, which reduces the need for SW to wait for the start of a VBLANK signal in order to ensure all states are loaded before the next VBLANK.
        0=PENDING ((none)); 1=WORKING ((none))
    0xF0 GCREGPANELFUNCTION — Panel function Register. NOTE.. This register is double buffered.
      [all] fields
        0=DISABLED ((none)); 1=ENABLED ((none))
      [2] GCREGPANELFUNCTION_DITHER — Enabling dithering allows R8G8B8 modes to show better on panels with less bits-per-pixel. NOTE: This field is double buffered.
      [1] GCREGPANELFUNCTION_GAMMA — When Gamma is enabled, the R, G, and B channels will be routed through the Gamma LUT to perform gamma correction. NOTE: This field is double buffered.
      [0] GCREGPANELFUNCTION_OUTPUT — When Output is enabled, pixels will be displayed. When Output is disabled, all pixels will be black. This allows a panel to have correct timing but without any pixels. NOTE: This field is double buffered.
    0xF4 GCREGPANELWORKING wo — Register to trigger Display Controller.
      [0] GCREGPANELWORKING_WORKING — Writing a one in this register will force a reset of the display controller. All registers will be copied to the working set and counters will be reset to the end of HSYNC and VSYNC.
        1=WORKING ((none))
    0xF8 GCREGPANELSTATE ro — Register representing the Display Controller status. READ ONLY.
      [all] fields
        0=NO ((none)); 1=YES ((none))
      [3] GCREGPANELSTATE_OVERLAY_UNDER_FLOW1 — When the overlay FIFO underflows, this bit gets set to one. Reading this register will reset it back to zero.
      [2] GCREGPANELSTATE_OVERLAY_UNDER_FLOW — When the overlay FIFO underflows, this bit gets set to one. Reading this register will reset it back to zero.
      [1] GCREGPANELSTATE_VIDEO_UNDER_FLOW — When the display FIFO underflows, this bit gets set to one. Reading this register will reset it back to zero.
    0x100 GCREGHDISPLAY — Horizontal Display Total and Visible Pixel Count Register. Horizontal Total and Display End counters. NOTE.. This register is double buffered.
      [28:16] GCREGHDISPLAY_TOTAL — Total number of horizontal pixels. NOTE: This field is double buffered.
      [12:0] GCREGHDISPLAY_DISPLAY_END — Number of visible horizontal pixels. NOTE: This field is double buffered.
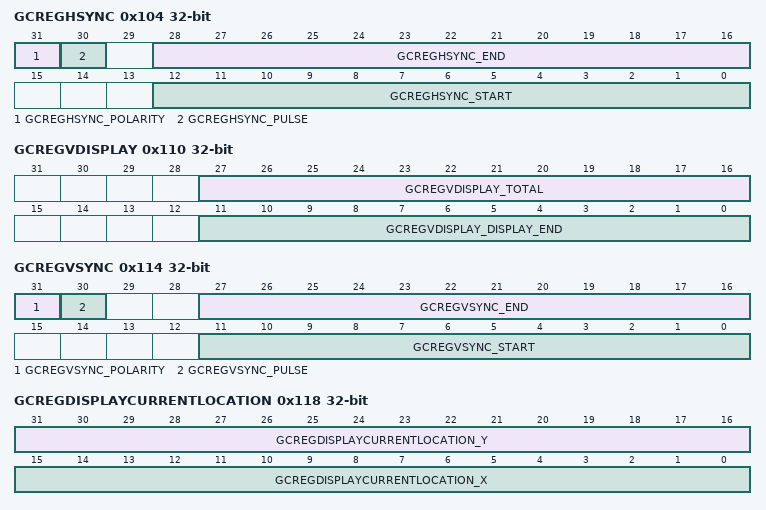
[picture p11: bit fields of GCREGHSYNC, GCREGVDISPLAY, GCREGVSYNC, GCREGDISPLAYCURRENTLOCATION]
    0x104 GCREGHSYNC — Horizontal Sync Counter Register. Horizontal Sync counters. NOTE.. This register is double buffered.
      [31] GCREGHSYNC_POLARITY — Polarity of the horizontal sync pulse. NOTE: This field is double buffered.
        0=POSITIVE ((none)); 1=NEGATIVE ((none))
      [30] GCREGHSYNC_PULSE — Horizontal sync pulse control. NOTE: This field is double buffered.
        0=DISABLED ((none)); 1=ENABLED ((none))
      [28:16] GCREGHSYNC_END — End of horizontal sync pulse. NOTE: This field is double buffered.
      [12:0] GCREGHSYNC_START — Start of horizontal sync pulse. NOTE: This field is double buffered.
    0x110 GCREGVDISPLAY — Vertical Total and Visible Pixel Count Register. Vertical Total and Display End counters. NOTE.. This register is double buffered.
      [27:16] GCREGVDISPLAY_TOTAL — Total number of vertical lines. NOTE: This field is double buffered.
      [11:0] GCREGVDISPLAY_DISPLAY_END — Number of visible vertical lines. NOTE: This field is double buffered.
    0x114 GCREGVSYNC — Vertical Sync Counter Register. Vertical Sync counters. NOTE.. This register is double buffered.
      [31] GCREGVSYNC_POLARITY — Polarity of the vertical sync pulse. NOTE: This field is double buffered.
        0=POSITIVE ((none)); 1=NEGATIVE ((none))
      [30] GCREGVSYNC_PULSE — Vertical sync pulse control. NOTE: This field is double buffered.
        0=DISABLED ((none)); 1=ENABLED ((none))
      [27:16] GCREGVSYNC_END — End of the vertical sync pulse. NOTE: This field is double buffered.
      [11:0] GCREGVSYNC_START — Start of the vertical sync pulse. NOTE: This field is double buffered.
    0x118 GCREGDISPLAYCURRENTLOCATION ro — Display Current Location Register. Current x,y location of display controller. READ ONLY.
      [31:16] GCREGDISPLAYCURRENTLOCATION_Y — Current Y location.
      [15:0] GCREGDISPLAYCURRENTLOCATION_X — Current X location.
    0x11C GCREGGAMMAINDEX wo — Gamma Index Register. Index into gamma table. See gcregGammaData for more information.
      [7:0] GCREGGAMMAINDEX_INDEX — Index into gamma table.
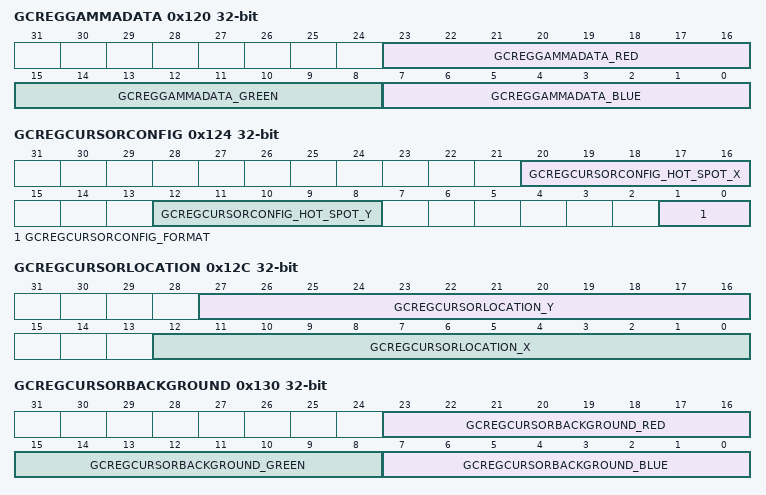
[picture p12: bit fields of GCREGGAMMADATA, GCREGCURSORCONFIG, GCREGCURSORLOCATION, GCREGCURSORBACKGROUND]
    0x120 GCREGGAMMADATA wo — Gamma Data Register. Translation values for the gamma table. When this register gets written, the data gets stored in the gamma table at the index specified by the gcregGammaIndex register. After the register is written, the index gets incremented.
      [23:16] GCREGGAMMADATA_RED — Red translation value.
      [15:8] GCREGGAMMADATA_GREEN — Green translation value.
      [7:0] GCREGGAMMADATA_BLUE — Blue translation value.
    0x124 GCREGCURSORCONFIG — Cursor Configuration Register. Configuration register for the cursor. Double-buffered values in this register cannot be read while a flip is in progress. NOTE.. This register is double buffered.
      [20:16] GCREGCURSORCONFIG_HOT_SPOT_X — Horizontal offset to cursor hotspot. NOTE: This field is double buffered.
      [12:8] GCREGCURSORCONFIG_HOT_SPOT_Y — Vertical offset to cursor hotspot. NOTE: This field is double buffered.
      [1:0] GCREGCURSORCONFIG_FORMAT — Format of the cursor. NOTE: This field is double buffered.
        0=DISABLED ((none)); 1=MASKED ((none)); 2=A8R8G8B8 ((none))
    0x128 GCREGCURSORADDRESS — Cursor Base Address Register. Address of the cursor shape. NOTE.. This register is double buffered.
      [31:0] GCREGCURSORADDRESS_ADDRESS — 32 bit address.
    0x12C GCREGCURSORLOCATION — Cursor Location Register. Location of the cursor on the owning display. NOTE.. This register is double buffered.
      [27:16] GCREGCURSORLOCATION_Y — Y location of cursor's hotspot. NOTE: This field is double buffered.
      [12:0] GCREGCURSORLOCATION_X — X location of cursor's hotspot. NOTE: This field is double buffered.
    0x130 GCREGCURSORBACKGROUND — Cursor Background Color Register. The background color for Masked cursors. NOTE.. This register is double buffered.
      [23:16] GCREGCURSORBACKGROUND_RED — Red value. NOTE: This field is double buffered.
      [15:8] GCREGCURSORBACKGROUND_GREEN — Green value. NOTE: This field is double buffered.
      [7:0] GCREGCURSORBACKGROUND_BLUE — Blue value. NOTE: This field is double buffered.
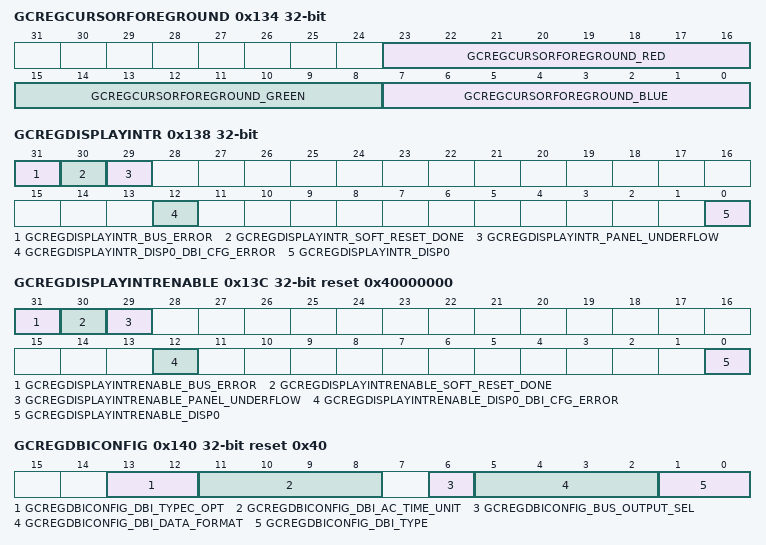
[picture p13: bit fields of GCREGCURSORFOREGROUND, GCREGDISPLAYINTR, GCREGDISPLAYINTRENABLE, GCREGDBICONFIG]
    0x134 GCREGCURSORFOREGROUND — Cursor Foreground Color Register. The foreground color for Masked cursors. NOTE.. This register is double buffered.
      [23:16] GCREGCURSORFOREGROUND_RED — Red value. NOTE: This field is double buffered.
      [15:8] GCREGCURSORFOREGROUND_GREEN — Green value. NOTE: This field is double buffered.
      [7:0] GCREGCURSORFOREGROUND_BLUE — Blue value. NOTE: This field is double buffered.
    0x138 GCREGDISPLAYINTR ro — Display Interrupt Register. This is the interrupt register for the Display. This register will automatically clear after a read. The interrupt bit is set when the current frame buffer is used up. The interrupt signal will be pulled up only when the interrupt enable bit in register gcregDisplayIntrEnable is enabled. READ ONLY. When the access comes from a debugger (HMASTER[0] == 1), the clear by read function is disabled.
      [31] GCREGDISPLAYINTR_BUS_ERROR — Bus error
      [30] GCREGDISPLAYINTR_SOFT_RESET_DONE — Soft reset done
      [29] GCREGDISPLAYINTR_PANEL_UNDERFLOW — Panel underflow intr.
      [12] GCREGDISPLAYINTR_DISP0_DBI_CFG_ERROR — Display0 DBI configure error
      [0] GCREGDISPLAYINTR_DISP0 — Display0 interrupt
    0x13C GCREGDISPLAYINTRENABLE reset 0x40000000 — Display Interrupt Enable Register. The interrupt enable register for display_0 (and display_1 if present). NOTE.. Interrupt enable for register gcregDisplayIntr. NOTE.. This register is double buffered.
      [31] GCREGDISPLAYINTRENABLE_BUS_ERROR — Bus error enable NOTE: This field is double buffered.
      [30] GCREGDISPLAYINTRENABLE_SOFT_RESET_DONE — Soft reset done enable NOTE: This field is double buffered.
      [29] GCREGDISPLAYINTRENABLE_PANEL_UNDERFLOW — Panel underflow intr enable. NOTE: This field is double buffered.
      [12] GCREGDISPLAYINTRENABLE_DISP0_DBI_CFG_ERROR — Display0 DBI configure error enable NOTE: This field is double buffered.
      [0] GCREGDISPLAYINTRENABLE_DISP0 — Display0 interrupt enable NOTE: This field is double buffered.
    0x140 GCREGDBICONFIG reset 0x40 — DBI Configuration Register. Configuration register for DBI output.
      [13:12] GCREGDBICONFIG_DBI_TYPEC_OPT — Options for DBI Type C Interface Read/Write Sequence; 0: Option 1; 1: Option 2; 2: Option 3.
      [11:8] GCREGDBICONFIG_DBI_AC_TIME_UNIT — Time unit for AC characteristics
      [6] GCREGDBICONFIG_BUS_OUTPUT_SEL — Output bus select
        0=DPI ((none)); 1=DBI ((none))
      [5:2] GCREGDBICONFIG_DBI_DATA_FORMAT — DBI interface data format. Refer to DBI specification section on Interface Color Coding for detail.
        0=D8R3G3B2 ((none)); 1=D8R4G4B4 ((none)); 2=D8R5G6B5 ((none)); 3=D8R6G6B6 ((none)); 4=D8R8G8B8 ((none)); 5=D9R6G6B6 ((none)); 6=D16R3G3B2 ((none)); 7=D16R4G4B4 ((none)); 8=D16R5G6B5 ((none)); 9=D16_R6_G6_B6_OP1 ((none)); 10=D16_R6_G6_B6_OP2 ((none)); 11=D16_R8_G8_B8_OP1 ((none)); 12=D16_R8_G8_B8_OP2 ((none)); 13=D1R5G6B5 ((none)); 14=D1R8G8B8 ((none))
      [1:0] GCREGDBICONFIG_DBI_TYPE — DBI Type select
        0=TYPE_AFIXED_E ((none)); 1=TYPE_ACLOCK_E ((none)); 2=TYPE_B ((none)); 3=TYPE_C ((none))
    0x144 GCREGDBIIFRESET wo — DBI Reset Register. Reset DBI interface to idle state. WRITE ONLY.
      [0] GCREGDBIIFRESET_DBI_IF_LEVEL_RESET — Reset DBI interface to idle state
        1=RESET ((none))
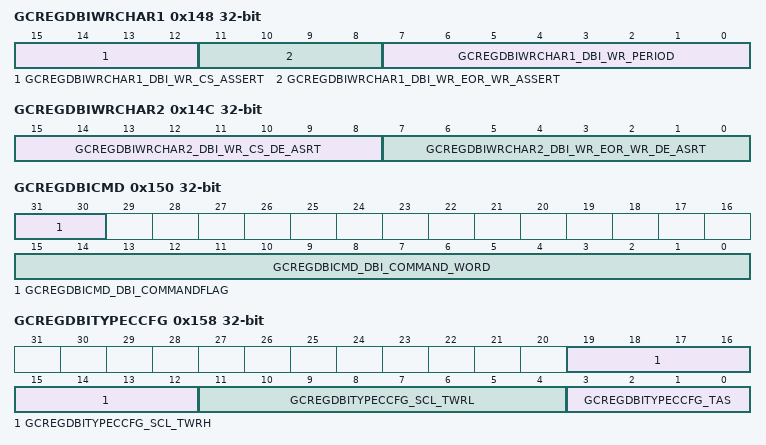
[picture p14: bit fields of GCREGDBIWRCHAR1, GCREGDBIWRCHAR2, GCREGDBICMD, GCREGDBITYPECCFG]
    0x148 GCREGDBIWRCHAR1 — DBI Write AC Characteristics 1 Register. DBI write AC characteristics definition register 1
      [15:12] GCREGDBIWRCHAR1_DBI_WR_CS_ASSERT — Cycle number=Setting*(DbiAcTimeUnit+1). 0: When Type A Fixed E mode: Time to assert CSX. 1: When Type A Clock E mode: Not used. 2: When Type B mode: Time to assert CSX.
      [11:8] GCREGDBIWRCHAR1_DBI_WR_EOR_WR_ASSERT — Cycle number=Setting*(DbiAcTimeUnit+1). 0: When Type A Fixed E mode: Not used. 1: When Type A Clock E mode: Time to assert E. 2: When Type B mode: Time to assert WRX.
      [7:0] GCREGDBIWRCHAR1_DBI_WR_PERIOD — Single write period duration. Cycle number=Setting*(DbiAcTimeUnit+1). This field must be no less than 3.
    0x14C GCREGDBIWRCHAR2 — DBI Write AC Characteristics 2 Register. DBI write AC characteristics definition register 2
      [15:8] GCREGDBIWRCHAR2_DBI_WR_CS_DE_ASRT — Cycle number=Setting*(DbiAcTimeUnit+1). 0: When type A fixed E mode: Time to de-assert CSX. 1: When type A clock E mode: Not used. 2: When type B mode: Time to de-assert CSX.
      [7:0] GCREGDBIWRCHAR2_DBI_WR_EOR_WR_DE_ASRT — Cycle number=Setting*(DbiAcTimeUnit+1). 0: When Type A Fixed E mode: Not used. 1: When type A Clock E mode: Time to de-assert E. 2: When Type B mode: Time to de-assert WRX.
    0x150 GCREGDBICMD wo — DBI Command Control Register. DBI Command in/out port. Writes to this register will send command/data to the DBI port. WRITE ONLY.
      [31:30] GCREGDBICMD_DBI_COMMANDFLAG — DBI command flag.
        0=ADDRESS (//DBI_COMMAND_WORD will contain an address.); 1=WRITE_MEM_START (//Starts a write. Contents of DBI_COMMAND_WORD are ignored.); 2=PARAMETER_OR_DATA (//DBI_COMMAND_WORD will contain a parameter or data.)
      [15:0] GCREGDBICMD_DBI_COMMAND_WORD — The type of data contained in this word is specified using DBI_COMMANDFLAG[bits 31:30]. For Type C Options 1 and 2: DBI_COMMAND_WORD[8] is used to indicate the polarity of D/CX. DBI_COMMAND_WORD[8] = 0 indicates DBI_COMMAND_WORD[7:0] is COMMAND WORD. DBI_COMMAND_WORD[8] = 1 indicates DBI_COMMAND_WORD[7:0] is DATA WORD.
    0x154 GCREGDPICONFIG reset 0x5 — DPI Configuration Register. The configuration register for DPI output. NOTE.. This register is double buffered.
      [2:0] GCREGDPICONFIG_DPI_DATA_FORMAT — DPI interface data format. Refer to DPI specification section for Interface Color Coding' for detail. NOTE: This field is double buffered.
        0=D16CFG1 ((none)); 1=D16CFG2 ((none)); 2=D16CFG3 ((none)); 3=D18CFG1 ((none)); 4=D18CFG2 ((none)); 5=D24 ((none))
    0x158 GCREGDBITYPECCFG — DBI Type C Timing Control Register. DBI Type C write timing definition.
      [19:12] GCREGDBITYPECCFG_SCL_TWRH — Divide counter for Twrh (SCL H duration (write)). Specifies how many sdaClk cycles in Twrh phase. SCL Twrh means number of DBI_AC_TIME_UNIT of sdaClk for scl staying high. This field need to be at least 1.
      [11:4] GCREGDBITYPECCFG_SCL_TWRL — Divide counter for Twrl (SCL L duration (write)). Specifies how many sdaClk cycles in Twrl phase. SCL Twrl means number of DBI_AC_TIME_UNIT of sdaClk for scl staying low This field needs to be at least 1.
      [3:0] GCREGDBITYPECCFG_TAS — Divide counter for Tas (address setup time). Specifies how many sdaClk cycles in Tas phase. DCX Tas means number of DBI_AC_TIME_UNIT of sdaClk to be ahead of scl. Only works for DBI TYPE C Option3. Option1/2 will ignore this setting. This field needs to be at least 1.
    0x15C GCREGDCSTATUS ro — Display Controller Status Register. READ ONLY.
      [0] GCREGDCSTATUS_DBI_TYPEC_FIFO_FULL — DBI Type C afifo full.
    0x160 GCREGSRCCONFIGENDIAN — Endian control.
      [1:0] GCREGSRCCONFIGENDIAN_CONTROL — Control source endian.
        0=NO_SWAP (No swapping.); 1=SWAP_WORD (Swap at 16-bit boundary: 0123 to 1032.); 2=SWAP_DWORD (Swap at 32-bit boundary: 0123 to 3210.)
    0x164 GCREGSOFTRESET wo — Soft reset. WRITE ONLY.
      [0] GCREGSOFTRESET_RESET — Writing a one in this register will force a soft reset of the display controller.
        1=RESET ((none))
    0x168 GCREGDCCONTROL — Control register.
      [4] GCREGDCCONTROL_RAM_CLOCK_GATING — Enable or disable ram clock gating.
        0=DISABLED ((none)); 1=ENABLED ((none))
      [3] GCREGDCCONTROL_DEBUG_REGISTER — Enable or disable the debug register.
        0=DISABLED ((none)); 1=ENABLED ((none))
    0x16C GCREGREGISTERTIMINGCONTROL — Timing control register.
      [22] GCREGREGISTERTIMINGCONTROL_LIGHT_SLEEP — (none)
      [21] GCREGREGISTERTIMINGCONTROL_DEEP_SLEEP — (none)
      [20] GCREGREGISTERTIMINGCONTROL_POWER_DOWN — (none)
      [19:18] GCREGREGISTERTIMINGCONTROL_FAST_WTC — (none)
      [17:16] GCREGREGISTERTIMINGCONTROL_FAST_RTC — (none)
      [15:8] GCREGREGISTERTIMINGCONTROL_FOR_RF2P — (none)
      [7:0] GCREGREGISTERTIMINGCONTROL_FOR_PF1P — (none)
    0x170 GCREGDEBUGCOUNTERSELECT — Debug Counter Select Register.
      [7:0] GCREGDEBUGCOUNTERSELECT_SELECT — Write a value to this field to pick up from 0~255 counters. Then the counter will be in gcregDebugCounterValue.
    0x174 GCREGDEBUGCOUNTERVALUE ro — Debug Counter Value Register. Debug Counter Value as specified in gcregDebugCounterSelect. READ ONLY
      [31:0] GCREGDEBUGCOUNTERVALUE_VALUE — Selected debug counter value
    0x1A0 GCREGLAYERCLOCKGATE — Layer clock gater Register. disable video/overlay0/overlay1 clock gater
      [all] fields
        0=DISABLED ((none)); 1=ENABLED ((none))
      [2] GCREGLAYERCLOCKGATE_DISABLE_OVERLAY1_CLK — (none)
      [1] GCREGLAYERCLOCKGATE_DISABLE_OVERLAY0_CLK — (none)
      [0] GCREGLAYERCLOCKGATE_DISABLE_VIDEO_CLK — (none)
    0x1A4 GCREGDEBUGTOTVIDEOREQ ro — debug registers.. count video current frame number of requested burst. READ ONLY
      [31:0] GCREGDEBUGTOTVIDEOREQ_NUM — (none)
    0x1A8 GCREGDEBUGLSTVIDEOREQ ro — debug registers.. count video last frame number of requested burst. READ ONLY
      [31:0] GCREGDEBUGLSTVIDEOREQ_NUM — (none)
    0x1AC GCREGDEBUGTOTVIDEORRB ro — debug registers.. count video current frame number of returned burst. READ ONLY
      [31:0] GCREGDEBUGTOTVIDEORRB_NUM — (none)
    0x1B0 GCREGDEBUGLSTVIDEORRB ro — debug registers.. count video last frame number of returned burst. READ ONLY
      [31:0] GCREGDEBUGLSTVIDEORRB_NUM — (none)
    0x1B4 GCREGDEBUGTOTOVERLAY0REQ ro — debug registers.. count overlay0 current frame number of requested burst. READ ONLY
      [31:0] GCREGDEBUGTOTOVERLAY0REQ_NUM — (none)
    0x1B8 GCREGDEBUGLSTOVERLAY0REQ ro — debug registers.. count overlay0 last frame number of requested burst. READ ONLY
      [31:0] GCREGDEBUGLSTOVERLAY0REQ_NUM — (none)
    0x1BC GCREGDEBUGTOTOVERLAY0RRB ro — debug registers.. count overlay0 current frame number of returned burst. READ ONLY
      [31:0] GCREGDEBUGTOTOVERLAY0RRB_NUM — (none)
    0x1C0 GCREGDEBUGLSTOVERLAY0RRB ro — debug registers.. count overlay0 last frame number of returned burst. READ ONLY
      [31:0] GCREGDEBUGLSTOVERLAY0RRB_NUM — (none)
    0x1C4 GCREGDEBUGTOTOVERLAY1REQ ro — debug registers.. count overlay1 current frame number of requested burst. READ ONLY
      [31:0] GCREGDEBUGTOTOVERLAY1REQ_NUM — (none)
    0x1C8 GCREGDEBUGLSTOVERLAY1REQ ro — debug registers.. count overlay1 last frame number of requested burst. READ ONLY
      [31:0] GCREGDEBUGLSTOVERLAY1REQ_NUM — (none)
    0x1CC GCREGDEBUGTOTOVERLAY1RRB ro — debug registers.. count overlay1 current frame number of returned burst. READ ONLY
      [31:0] GCREGDEBUGTOTOVERLAY1RRB_NUM — (none)
    0x1D0 GCREGDEBUGLSTOVERLAY1RRB ro — debug registers.. count overlay1 last frame number of returned burst. READ ONLY
      [31:0] GCREGDEBUGLSTOVERLAY1RRB_NUM — (none)
    0x1D4 GCREGDEBUGTOTCURSORREQ ro — debug registers.. count cursor current frame number of requested burst. READ ONLY
      [31:0] GCREGDEBUGTOTCURSORREQ_NUM — (none)
    0x1D8 GCREGDEBUGLSTCURSORREQ ro — debug registers.. count cursor last frame number of requested burst. READ ONLY
      [31:0] GCREGDEBUGLSTCURSORREQ_NUM — (none)
    0x1DC GCREGDEBUGTOTCURSORRRB ro — debug registers.. count cursor current frame number of returned burst. READ ONLY
      [31:0] GCREGDEBUGTOTCURSORRRB_NUM — (none)
    0x1E0 GCREGDEBUGLSTCURSORRRB ro — debug registers.. count cursor last frame number of returned burst. READ ONLY
      [31:0] GCREGDEBUGLSTCURSORRRB_NUM — (none)
    0x1E4 GCREGDEBUGTOTDCREQ ro — debug registers.. count DC current frame number of requested burst. READ ONLY
      [31:0] GCREGDEBUGTOTDCREQ_NUM — (none)
    0x1E8 GCREGDEBUGLSTDCREQ ro — debug registers.. count DC last frame number of requested burst. READ ONLY
      [31:0] GCREGDEBUGLSTDCREQ_NUM — (none)
    0x1EC GCREGDEBUGTOTDCRRB ro — debug registers.. count DC current frame number of returned burst. READ ONLY
      [31:0] GCREGDEBUGTOTDCRRB_NUM — (none)
    0x1F0 GCREGDEBUGLSTDCRRB ro — debug registers.. count DC last frame number of returned burst. READ ONLY
      [31:0] GCREGDEBUGLSTDCRRB_NUM — (none)
    0x1F4 GCREGDEBUGFRAMEANDMISFLAG ro — debug registers. READ ONLY
      [31:21] GCREGDEBUGFRAMEANDMISFLAG_LAST_FRAME_CNT — debug registers: count DC last frame number
      [20:17] GCREGDEBUGFRAMEANDMISFLAG_LAST_MISMATCH_FLAG — debug registers: indicate each layer last frame mismatch of request and rerurn back number
      [16] GCREGDEBUGFRAMEANDMISFLAG_LAST_MISMATCH_FLAG_TOTAL — debug registers: indicate DC last frame mismatch of request and rerurn back number
      [15:5] GCREGDEBUGFRAMEANDMISFLAG_CURRENT_FRAME_CNT — debug registers: count DC current frame number
      [4:1] GCREGDEBUGFRAMEANDMISFLAG_CURRENT_MISMATCH_FLAG — debug registers: indicate each layer current frame mismatch of request and rerurn back number
      [0] GCREGDEBUGFRAMEANDMISFLAG_CURRENT_MISMATCH_FLAG_TOTAL — debug registers: indicate DC current frame mismatch of request and rerurn back number
